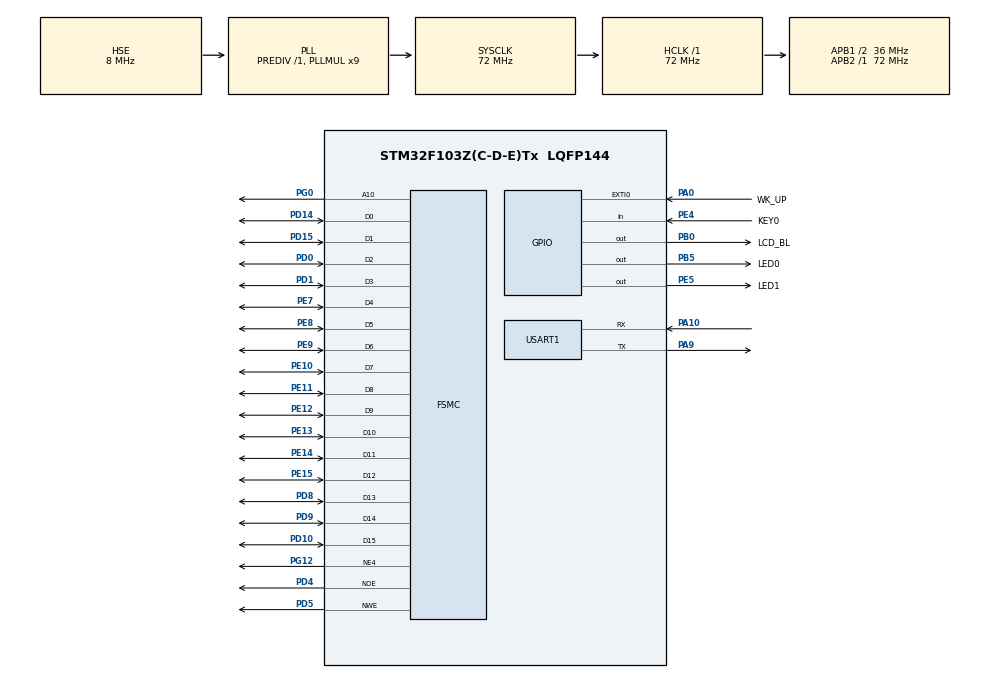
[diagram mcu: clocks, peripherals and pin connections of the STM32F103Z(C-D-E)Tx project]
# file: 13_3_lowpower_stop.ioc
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FSMC.AddressSetupTime1=0
FSMC.DataSetupTime1=15
FSMC.ExtendedAddressSetupTime1=0
FSMC.ExtendedDataSetupTime1=1
FSMC.ExtendedMode1=FSMC_EXTENDED_MODE_ENABLE
Mcu.Family=STM32F1
Mcu.Name=STM32F103Z(C-D-E)Tx
Mcu.Package=LQFP144
NVIC.EXTI0_IRQn=true\:2\:2\:true\:false\:true\:true\:true\:true
NVIC.PriorityGroup=NVIC_PRIORITYGROUP_2
NVIC.USART1_IRQn=true\:2\:2\:true\:false\:true\:true\:true\:true
OSC_IN.Mode=HSE-External-Oscillator
OSC_IN.Signal=RCC_OSC_IN
OSC_OUT.Mode=HSE-External-Oscillator
OSC_OUT.Signal=RCC_OSC_OUT
PA0-WKUP.GPIO_Label=WK_UP
PA0-WKUP.GPIO_PuPd=GPIO_PULLDOWN
PA0-WKUP.Signal=GPXTI0
PA10.Mode=Asynchronous
PA10.Signal=USART1_RX
PA13.Mode=Serial_Wire
PA13.Signal=SYS_JTMS-SWDIO
PA14.Mode=Serial_Wire
PA14.Signal=SYS_JTCK-SWCLK
PA9.Mode=Asynchronous
PA9.Signal=USART1_TX
PB0.GPIO_Label=LCD_BL
PB0.GPIO_PuPd=GPIO_PULLUP
PB0.GPIO_Speed=GPIO_SPEED_FREQ_HIGH
PB0.PinState=GPIO_PIN_SET
PB0.Signal=GPIO_Output
PB5.GPIO_Label=LED0
PB5.GPIO_PuPd=GPIO_PULLDOWN
PB5.GPIO_Speed=GPIO_SPEED_FREQ_HIGH
PB5.PinState=GPIO_PIN_SET
PB5.Signal=GPIO_Output
PC14-OSC32_IN.Mode=LSE-External-Oscillator
PC14-OSC32_IN.Signal=RCC_OSC32_IN
PC15-OSC32_OUT.Mode=LSE-External-Oscillator
PC15-OSC32_OUT.Signal=RCC_OSC32_OUT
PD0.Signal=FSMC_D2_DA2
PD1.Signal=FSMC_D3_DA3
PD10.Signal=FSMC_D15_DA15
PD14.Signal=FSMC_D0_DA0
PD15.Signal=FSMC_D1_DA1
PD4.Signal=FSMC_NOE
PD5.Signal=FSMC_NWE
PD8.Signal=FSMC_D13_DA13
PD9.Signal=FSMC_D14_DA14
PE10.Signal=FSMC_D7_DA7
PE11.Signal=FSMC_D8_DA8
PE12.Signal=FSMC_D9_DA9
PE13.Signal=FSMC_D10_DA10
PE14.Signal=FSMC_D11_DA11
PE15.Signal=FSMC_D12_DA12
PE4.GPIO_Label=KEY0
PE4.GPIO_PuPd=GPIO_PULLDOWN
PE4.Signal=GPIO_Input
PE5.GPIO_Label=LED1
PE5.GPIO_PuPd=GPIO_PULLDOWN
PE5.GPIO_Speed=GPIO_SPEED_FREQ_HIGH
PE5.PinState=GPIO_PIN_SET
PE5.Signal=GPIO_Output
PE7.Signal=FSMC_D4_DA4
PE8.Signal=FSMC_D5_DA5
PE9.Signal=FSMC_D6_DA6
PG0.Signal=FSMC_A10
PG12.Mode=NorPsramChipSelect4_1
PG12.Signal=FSMC_NE4
ProjectManager.HeapSize=0x200
ProjectManager.StackSize=0x400
ProjectManager.TargetToolchain=STM32CubeIDE
RCC.AHBFreq_Value=72000000
RCC.APB1CLKDivider=RCC_HCLK_DIV2
RCC.APB1Freq_Value=36000000
RCC.APB1TimFreq_Value=72000000
RCC.APB2Freq_Value=72000000
RCC.APB2TimFreq_Value=72000000
RCC.HCLKFreq_Value=72000000
RCC.PLLMUL=RCC_PLL_MUL9
RCC.PLLSourceVirtual=RCC_PLLSOURCE_HSE
RCC.SYSCLKFreq_VALUE=72000000
RCC.SYSCLKSource=RCC_SYSCLKSOURCE_PLLCLK
RCC.USBFreq_Value=72000000
SH.FSMC_A10.0=FSMC_A10,A10_1
SH.FSMC_D0_DA0.0=FSMC_D0,16b-d1
SH.FSMC_D10_DA10.0=FSMC_D10,16b-d1
SH.FSMC_D11_DA11.0=FSMC_D11,16b-d1
SH.FSMC_D12_DA12.0=FSMC_D12,16b-d1
SH.FSMC_D13_DA13.0=FSMC_D13,16b-d1
SH.FSMC_D14_DA14.0=FSMC_D14,16b-d1
SH.FSMC_D15_DA15.0=FSMC_D15,16b-d1
SH.FSMC_D1_DA1.0=FSMC_D1,16b-d1
SH.FSMC_D2_DA2.0=FSMC_D2,16b-d1
SH.FSMC_D3_DA3.0=FSMC_D3,16b-d1
SH.FSMC_D4_DA4.0=FSMC_D4,16b-d1
SH.FSMC_D5_DA5.0=FSMC_D5,16b-d1
SH.FSMC_D6_DA6.0=FSMC_D6,16b-d1
SH.FSMC_D7_DA7.0=FSMC_D7,16b-d1
SH.FSMC_D8_DA8.0=FSMC_D8,16b-d1
SH.FSMC_D9_DA9.0=FSMC_D9,16b-d1
SH.FSMC_NOE.0=FSMC_NOE,Lcd1
SH.FSMC_NWE.0=FSMC_NWE,Lcd1
USART1.VirtualMode=VM_ASYNC
board=custom

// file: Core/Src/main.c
/* USER CODE BEGIN Header */
/**
 ****************************************************************************************************
 * @file        main.c
 * @author      ALIENTEK
 * @brief       lowpower_stop code
 * @license     Copyright (C) 2012-2024, ALIENTEK
 ****************************************************************************************************
 * @attention
 *
 * platform     : ALIENTEK M144-STM32F103 board
 * website      : www.alientek.com
 * forum        : www.openedv.com/forum.php
 *
 * change logs  :
 * version      data         notes
 * V1.0         20240410     the first version
 *
 ****************************************************************************************************
 */
/* USER CODE END Header */
#include "main.h"
#include "usart.h"
#include "gpio.h"
#include "fsmc.h"

/* USER CODE BEGIN Includes */
#include "../../BSP/LED/led.h"
#include "../../BSP/KEY/key.h"
#include "../../BSP/LCD/lcd.h"
#include "../../BSP/PWR/pwr.h"
/* USER CODE END Includes */

void SystemClock_Config(void);

int main(void)
{
  /* USER CODE BEGIN 1 */
    uint8_t key;
    uint8_t t = 0;

  /* USER CODE END 1 */

  /* MCU Configuration--------------------------------------------------------*/

  /* Reset of all peripherals, Initializes the Flash interface and the Systick. */
  HAL_Init();

  /* Configure the system clock */
  SystemClock_Config();

  /* Initialize all configured peripherals */
  MX_GPIO_Init();
  MX_USART1_UART_Init();
  MX_FSMC_Init();
  /* USER CODE BEGIN 2 */
  lcd_init();

  lcd_show_string(30, 50, 200, 16, 16, "STM32", RED);
  lcd_show_string(30, 70, 200, 16, 16, "SLEEP TEST", RED);
  lcd_show_string(30, 90, 200, 16, 16, "ATOM@ALIENTEK", RED);

  lcd_show_string(30, 110, 200, 16, 16, "KEY0:Enter STOP MODE", RED);
  lcd_show_string(30, 130, 200, 16, 16, "KEY_UP:Exit STOP MODE", RED);

  /* USER CODE END 2 */

  /* Infinite loop */
  while (1)
  {

      key = key_scan(0);

      if (key == KEY0_PRES)
      {
    	  /* Press KEY0 to turn on LED1 and enter sleep mode */
    	  LED1(0);
    	  pwr_enter_stop();		/* Enter stop mode */
    	  LED1(1);
      }

      if (++t == 20)
      {
          t = 0;
          LED0_TOGGLE();
      }

	  HAL_Delay(10);

  }
}

void SystemClock_Config(void)
{
  RCC_OscInitTypeDef RCC_OscInitStruct = {0};
  RCC_ClkInitTypeDef RCC_ClkInitStruct = {0};

  /** Initializes the RCC Oscillators according to the specified parameters
  * in the RCC_OscInitTypeDef structure.
  */
  RCC_OscInitStruct.OscillatorType = RCC_OSCILLATORTYPE_HSE;
  RCC_OscInitStruct.HSEState = RCC_HSE_ON;
  RCC_OscInitStruct.HSEPredivValue = RCC_HSE_PREDIV_DIV1;
  RCC_OscInitStruct.HSIState = RCC_HSI_ON;
  RCC_OscInitStruct.PLL.PLLState = RCC_PLL_ON;
  RCC_OscInitStruct.PLL.PLLSource = RCC_PLLSOURCE_HSE;
  RCC_OscInitStruct.PLL.PLLMUL = RCC_PLL_MUL9;
  if (HAL_RCC_OscConfig(&RCC_OscInitStruct) != HAL_OK)
  {
    Error_Handler();
  }

  /** Initializes the CPU, AHB and APB buses clocks
  */
  RCC_ClkInitStruct.ClockType = RCC_CLOCKTYPE_HCLK|RCC_CLOCKTYPE_SYSCLK
                              |RCC_CLOCKTYPE_PCLK1|RCC_CLOCKTYPE_PCLK2;
  RCC_ClkInitStruct.SYSCLKSource = RCC_SYSCLKSOURCE_PLLCLK;
  RCC_ClkInitStruct.AHBCLKDivider = RCC_SYSCLK_DIV1;
  RCC_ClkInitStruct.APB1CLKDivider = RCC_HCLK_DIV2;
  RCC_ClkInitStruct.APB2CLKDivider = RCC_HCLK_DIV1;

  if (HAL_RCC_ClockConfig(&RCC_ClkInitStruct, FLASH_LATENCY_2) != HAL_OK)
  {
    Error_Handler();
  }
}

void Error_Handler(void)
{
  __disable_irq();
  while (1)
  {
  }
}
